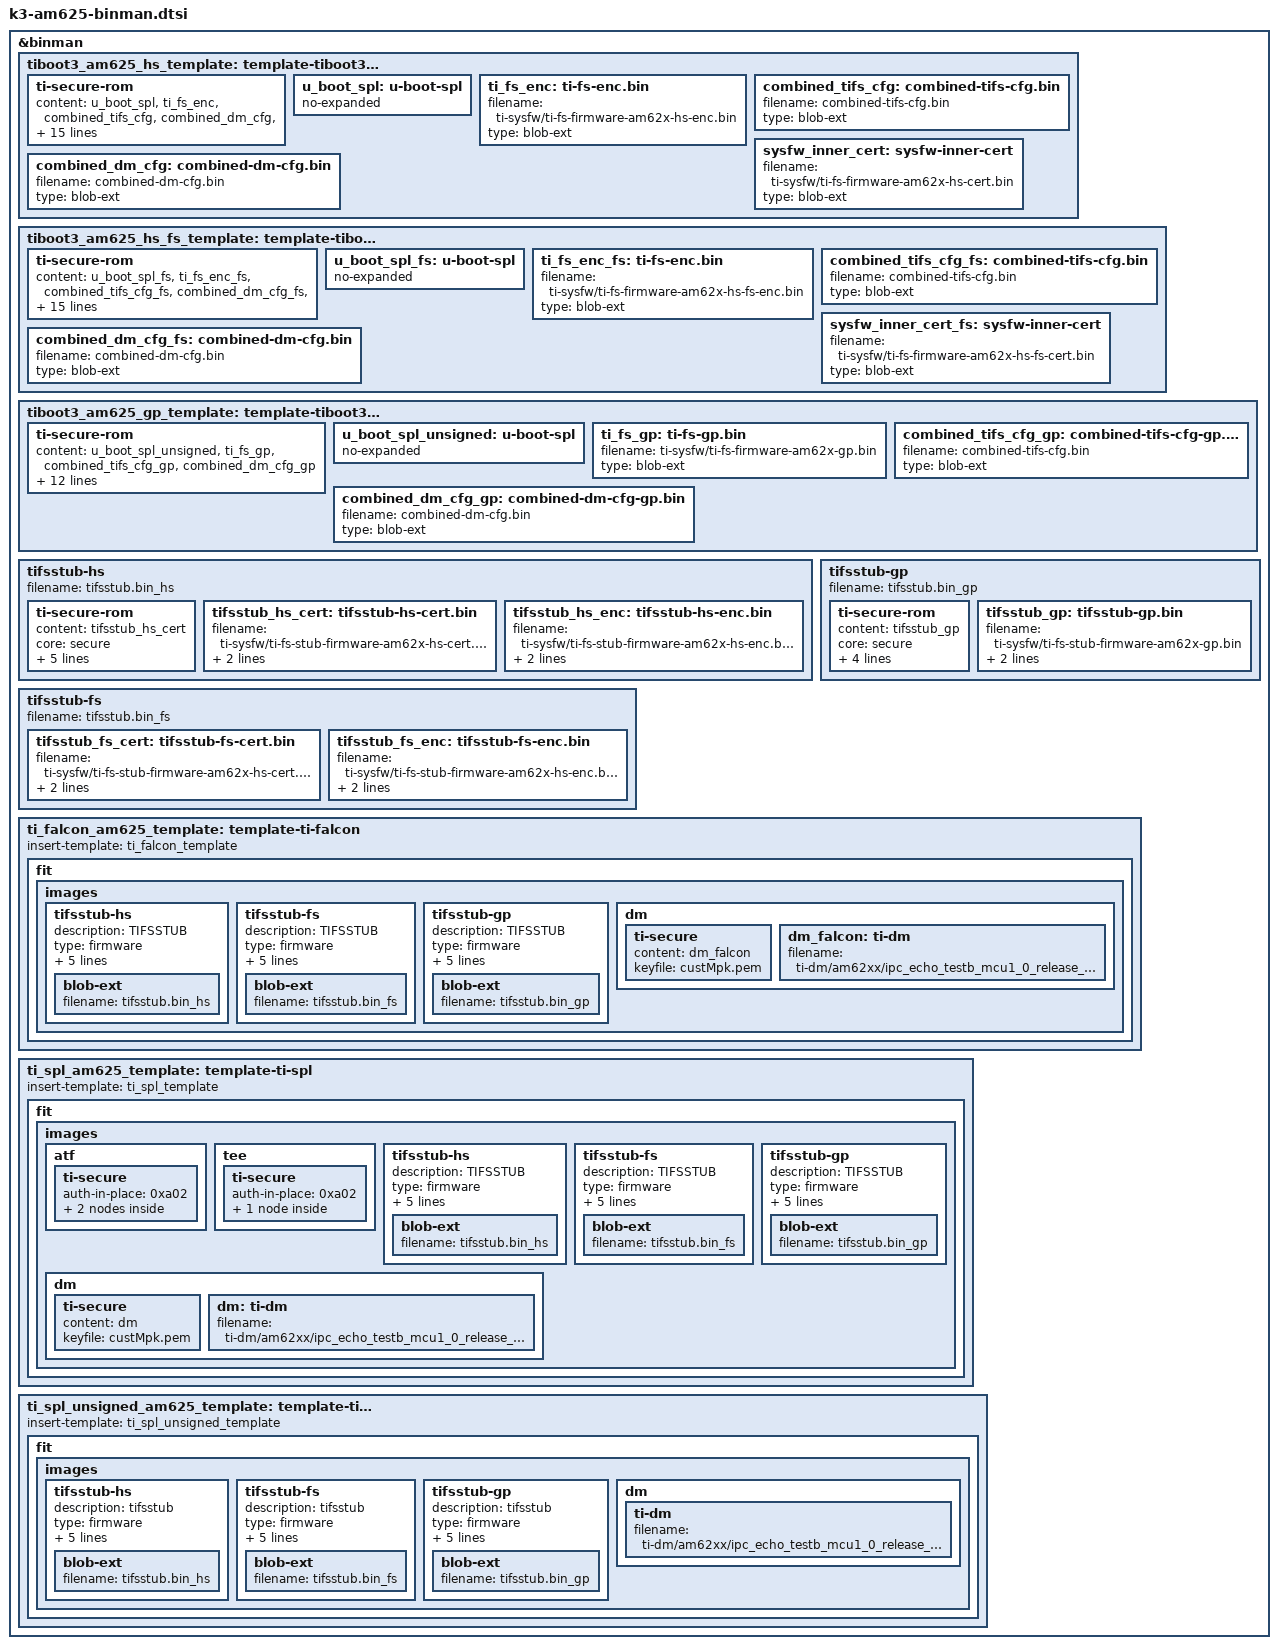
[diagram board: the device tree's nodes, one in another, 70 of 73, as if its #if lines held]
// SPDX-License-Identifier: GPL-2.0
/*
 * Copyright (C) 2026 Texas Instruments Incorporated - https://www.ti.com/
 */

#include "k3-binman.dtsi"

&binman {
	tiboot3_am625_hs_template: template-tiboot3-hs {
		ti-secure-rom {
			content = <&u_boot_spl>, <&ti_fs_enc>, <&combined_tifs_cfg>,
				  <&combined_dm_cfg>, <&sysfw_inner_cert>;
			combined;
			dm-data;
			sysfw-inner-cert;
			keyfile = "custMpk.pem";
			sw-rev = <1>;
			content-sbl = <&u_boot_spl>;
			content-sysfw = <&ti_fs_enc>;
			content-sysfw-data = <&combined_tifs_cfg>;
			content-sysfw-inner-cert = <&sysfw_inner_cert>;
			content-dm-data = <&combined_dm_cfg>;
			load = <CONFIG_SPL_TEXT_BASE>;
			load-sysfw = <0x40000>;
			load-sysfw-data = <0x67000>;
			load-dm-data = <0x43c3a800>;
		};
		u_boot_spl: u-boot-spl {
			no-expanded;
		};
		ti_fs_enc: ti-fs-enc.bin {
			filename = "ti-sysfw/ti-fs-firmware-am62x-hs-enc.bin";
			type = "blob-ext";
		};
		combined_tifs_cfg: combined-tifs-cfg.bin {
			filename = "combined-tifs-cfg.bin";
			type = "blob-ext";
		};
		sysfw_inner_cert: sysfw-inner-cert {
			filename = "ti-sysfw/ti-fs-firmware-am62x-hs-cert.bin";
			type = "blob-ext";
		};
		combined_dm_cfg: combined-dm-cfg.bin {
			filename = "combined-dm-cfg.bin";
			type = "blob-ext";
		};
	};

	tiboot3_am625_hs_fs_template: template-tiboot3-hs-fs {
		ti-secure-rom {
			content = <&u_boot_spl_fs>, <&ti_fs_enc_fs>, <&combined_tifs_cfg_fs>,
				  <&combined_dm_cfg_fs>, <&sysfw_inner_cert_fs>;
			combined;
			dm-data;
			sysfw-inner-cert;
			keyfile = "custMpk.pem";
			sw-rev = <1>;
			content-sbl = <&u_boot_spl_fs>;
			content-sysfw = <&ti_fs_enc_fs>;
			content-sysfw-data = <&combined_tifs_cfg_fs>;
			content-sysfw-inner-cert = <&sysfw_inner_cert_fs>;
			content-dm-data = <&combined_dm_cfg_fs>;
			load = <CONFIG_SPL_TEXT_BASE>;
			load-sysfw = <0x40000>;
			load-sysfw-data = <0x67000>;
			load-dm-data = <0x43c3a800>;
		};
		u_boot_spl_fs: u-boot-spl {
			no-expanded;
		};
		ti_fs_enc_fs: ti-fs-enc.bin {
			filename = "ti-sysfw/ti-fs-firmware-am62x-hs-fs-enc.bin";
			type = "blob-ext";
		};
		combined_tifs_cfg_fs: combined-tifs-cfg.bin {
			filename = "combined-tifs-cfg.bin";
			type = "blob-ext";
		};
		sysfw_inner_cert_fs: sysfw-inner-cert {
			filename = "ti-sysfw/ti-fs-firmware-am62x-hs-fs-cert.bin";
			type = "blob-ext";
		};
		combined_dm_cfg_fs: combined-dm-cfg.bin {
			filename = "combined-dm-cfg.bin";
			type = "blob-ext";
		};
	};

	tiboot3_am625_gp_template: template-tiboot3-gp {
		ti-secure-rom {
			content = <&u_boot_spl_unsigned>, <&ti_fs_gp>,
				<&combined_tifs_cfg_gp>, <&combined_dm_cfg_gp>;
			combined;
			dm-data;
			keyfile = "ti-degenerate-key.pem";
			sw-rev = <1>;
			content-sbl = <&u_boot_spl_unsigned>;
			content-sysfw = <&ti_fs_gp>;
			content-sysfw-data = <&combined_tifs_cfg_gp>;
			content-dm-data = <&combined_dm_cfg_gp>;
			load = <CONFIG_SPL_TEXT_BASE>;
			load-sysfw = <0x40000>;
			load-sysfw-data = <0x67000>;
			load-dm-data = <0x43c3a800>;
		};
		u_boot_spl_unsigned: u-boot-spl {
			no-expanded;
		};
		ti_fs_gp: ti-fs-gp.bin {
			filename = "ti-sysfw/ti-fs-firmware-am62x-gp.bin";
			type = "blob-ext";
		};
		combined_tifs_cfg_gp: combined-tifs-cfg-gp.bin {
			filename = "combined-tifs-cfg.bin";
			type = "blob-ext";
		};
		combined_dm_cfg_gp: combined-dm-cfg-gp.bin {
			filename = "combined-dm-cfg.bin";
			type = "blob-ext";
		};
	};
};

#ifdef CONFIG_ARM64

&binman {
	tifsstub-hs {
		filename = "tifsstub.bin_hs";
		ti-secure-rom {
			content = <&tifsstub_hs_cert>;
			core = "secure";
			load = <0x40000>;
			sw-rev = <CONFIG_K3_X509_SWRV>;
			keyfile = "custMpk.pem";
			countersign;
			tifsstub;
		};
		tifsstub_hs_cert: tifsstub-hs-cert.bin {
			filename = "ti-sysfw/ti-fs-stub-firmware-am62x-hs-cert.bin";
			type = "blob-ext";
			optional;
		};
		tifsstub_hs_enc: tifsstub-hs-enc.bin {
			filename = "ti-sysfw/ti-fs-stub-firmware-am62x-hs-enc.bin";
			type = "blob-ext";
			optional;
		};
	};

	tifsstub-fs {
		filename = "tifsstub.bin_fs";
		tifsstub_fs_cert: tifsstub-fs-cert.bin {
			filename = "ti-sysfw/ti-fs-stub-firmware-am62x-hs-cert.bin";
			type = "blob-ext";
			optional;
		};
		tifsstub_fs_enc: tifsstub-fs-enc.bin {
			filename = "ti-sysfw/ti-fs-stub-firmware-am62x-hs-enc.bin";
			type = "blob-ext";
			optional;
		};
	};

	tifsstub-gp {
		filename = "tifsstub.bin_gp";
		ti-secure-rom {
			content = <&tifsstub_gp>;
			core = "secure";
			load = <0x60000>;
			sw-rev = <CONFIG_K3_X509_SWRV>;
			keyfile = "ti-degenerate-key.pem";
			tifsstub;
		};
		tifsstub_gp: tifsstub-gp.bin {
			filename = "ti-sysfw/ti-fs-stub-firmware-am62x-gp.bin";
			type = "blob-ext";
			optional;
		};
	};

	ti_falcon_am625_template: template-ti-falcon {
		insert-template = <&ti_falcon_template>;
		fit {
			images {
				tifsstub-hs {
					description = "TIFSSTUB";
					type = "firmware";
					arch = "arm32";
					compression = "none";
					os = "tifsstub-hs";
					load = <0x9dc00000>;
					entry = <0x9dc00000>;
					blob-ext {
						filename = "tifsstub.bin_hs";
					};
				};
				tifsstub-fs {
					description = "TIFSSTUB";
					type = "firmware";
					arch = "arm32";
					compression = "none";
					os = "tifsstub-fs";
					load = <0x9dc00000>;
					entry = <0x9dc00000>;
					blob-ext {
						filename = "tifsstub.bin_fs";
					};
				};
				tifsstub-gp {
					description = "TIFSSTUB";
					type = "firmware";
					arch = "arm32";
					compression = "none";
					os = "tifsstub-gp";
					load = <0x9dc00000>;
					entry = <0x9dc00000>;
					blob-ext {
						filename = "tifsstub.bin_gp";
					};
				};
				dm {
					ti-secure {
						content = <&dm_falcon>;
						keyfile = "custMpk.pem";
					};
					dm_falcon: ti-dm {
						filename = "ti-dm/am62xx/ipc_echo_testb_mcu1_0_release_strip.xer5f";
					};
				};
			};
		};
	};

	ti_spl_am625_template: template-ti-spl {
		insert-template = <&ti_spl_template>;
		fit {
			images {
				atf {
					ti-secure {
						auth-in-place = <0xa02>;
						firewall-1-0 {
							insert-template = <&firewall_bg_3>;
							id = <1>;
							region = <0>;
						};
						firewall-1-1 {
							insert-template = <&firewall_armv8_atf_fg>;
							id = <1>;
							region = <1>;
						};
					};
				};
				tee {
					ti-secure {
						auth-in-place = <0xa02>;
						firewall-1-2 {
							insert-template = <&firewall_armv8_optee_fg>;
							id = <1>;
							region = <2>;
						};
					};
				};
				tifsstub-hs {
					description = "TIFSSTUB";
					type = "firmware";
					arch = "arm32";
					compression = "none";
					os = "tifsstub-hs";
					load = <0x9dc00000>;
					entry = <0x9dc00000>;
					blob-ext {
						filename = "tifsstub.bin_hs";
					};
				};
				tifsstub-fs {
					description = "TIFSSTUB";
					type = "firmware";
					arch = "arm32";
					compression = "none";
					os = "tifsstub-fs";
					load = <0x9dc00000>;
					entry = <0x9dc00000>;
					blob-ext {
						filename = "tifsstub.bin_fs";
					};
				};
				tifsstub-gp {
					description = "TIFSSTUB";
					type = "firmware";
					arch = "arm32";
					compression = "none";
					os = "tifsstub-gp";
					load = <0x9dc00000>;
					entry = <0x9dc00000>;
					blob-ext {
						filename = "tifsstub.bin_gp";
					};
				};
				dm {
					ti-secure {
						content = <&dm>;
						keyfile = "custMpk.pem";
					};
					dm: ti-dm {
						filename = "ti-dm/am62xx/ipc_echo_testb_mcu1_0_release_strip.xer5f";
					};
				};
			};
		};
	};

	ti_spl_unsigned_am625_template: template-ti-spl_unsigned {
		insert-template = <&ti_spl_unsigned_template>;
		fit {
			images {
				tifsstub-hs {
					description = "tifsstub";
					type = "firmware";
					arch = "arm32";
					compression = "none";
					os = "tifsstub-hs";
					load = <0x9dc00000>;
					entry = <0x9dc00000>;
					blob-ext {
						filename = "tifsstub.bin_hs";
					};
				};
				tifsstub-fs {
					description = "tifsstub";
					type = "firmware";
					arch = "arm32";
					compression = "none";
					os = "tifsstub-fs";
					load = <0x9dc00000>;
					entry = <0x9dc00000>;
					blob-ext {
						filename = "tifsstub.bin_fs";
					};
				};
				tifsstub-gp {
					description = "tifsstub";
					type = "firmware";
					arch = "arm32";
					compression = "none";
					os = "tifsstub-gp";
					load = <0x9dc00000>;
					entry = <0x9dc00000>;
					blob-ext {
						filename = "tifsstub.bin_gp";
					};
				};
				dm {
					ti-dm {
						filename = "ti-dm/am62xx/ipc_echo_testb_mcu1_0_release_strip.xer5f";
					};
				};
			};
		};
	};
};

#endif
